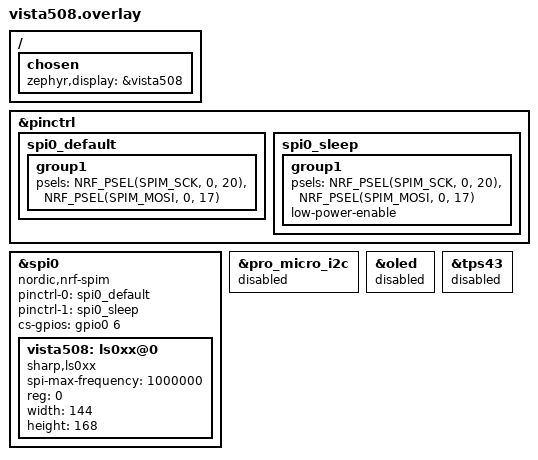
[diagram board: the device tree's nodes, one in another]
/*
 * Copyright (c) 2022 The ZMK Contributors
 *
 * SPDX-License-Identifier: MIT
 */

// Enable SPI for the Vista508 MIP display (SCK=P0.20, MOSI=P0.17, CS=P0.06).
&pinctrl {
    spi0_default: spi0_default {
        group1 {
            psels = <NRF_PSEL(SPIM_SCK, 0, 20)>,
                <NRF_PSEL(SPIM_MOSI, 0, 17)>;
        };
    };

    spi0_sleep: spi0_sleep {
        group1 {
            psels = <NRF_PSEL(SPIM_SCK, 0, 20)>,
                <NRF_PSEL(SPIM_MOSI, 0, 17)>;
            low-power-enable;
        };
    };
};

nice_view_spi: &spi0 {
    compatible = "nordic,nrf-spim";
    pinctrl-0 = <&spi0_default>;
    pinctrl-1 = <&spi0_sleep>;
    pinctrl-names = "default", "sleep";
    cs-gpios = <&gpio0 6 GPIO_ACTIVE_HIGH>;
};

&pro_micro_i2c {
    status = "disabled";
};

&oled {
    status = "disabled";
};

&tps43 {
    status = "disabled";
};

&nice_view_spi {
    status = "okay";
    vista508: ls0xx@0 {
        compatible = "sharp,ls0xx";
        spi-max-frequency = <1000000>;
        reg = <0>;
        width = <144>;
        height = <168>;
    };
};

/ {
    chosen {
        zephyr,display = &vista508;
    };
};
